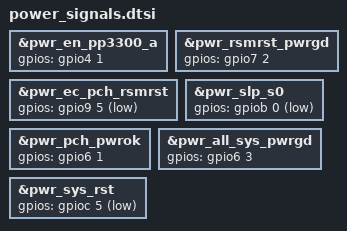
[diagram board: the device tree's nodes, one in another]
/* Copyright 2025 The ChromiumOS Authors
 * Use of this source code is governed by a BSD-style license that can be
 * found in the LICENSE file.
 */

#include "../power_signals.dtsi"

&pwr_en_pp3300_a {
        /* NB_C_EC_DS3 net. This connects to the PRIM_VR_EN signal and
         * both the EN1 and EN2 pins on the RT6585 LDO. */
	gpios = <&gpio4 1 GPIO_ACTIVE_HIGH>;
};
&pwr_rsmrst_pwrgd {
        /* RSMRST_PWRGD_N_R net  */
	gpios = <&gpio7 2 (GPIO_ACTIVE_HIGH | GPIO_VOLTAGE_1P8)>;
};
&pwr_ec_pch_rsmrst {
        /* RM_RSMST_N_R net */
	gpios = <&gpio9 5 GPIO_ACTIVE_LOW>;
};
&pwr_slp_s0 {
        /* PCH_SLP_S0_N_R net */
	gpios = <&gpiob 0 GPIO_ACTIVE_LOW>;
};
&pwr_pch_pwrok {
        /* PCH_PWROK_EC_R net */
	gpios = <&gpio6 1 GPIO_ACTIVE_HIGH>;
};
&pwr_all_sys_pwrgd {
        /* ALL_SYS_PWRGD_R net */
	gpios = <&gpio6 3 GPIO_ACTIVE_HIGH>;
};
&pwr_sys_rst {
        gpios = <&gpioc 5 (GPIO_ACTIVE_LOW|GPIO_OPEN_DRAIN)>;
};
